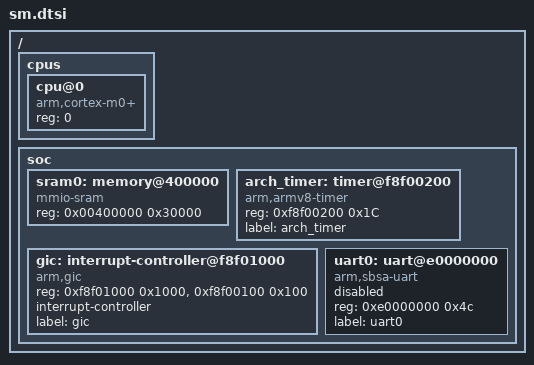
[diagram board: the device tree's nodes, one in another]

/*
 * Copyright (c) 2021 Samsung
 * SPDX-License-Identifier: Apache-2.0
 */

 #include <mem.h>
 #include <arm/armv7-a.dtsi>
 #include <dt-bindings/interrupt-controller/arm-gic.h>

/{
      cpus{
	#address-cells=<1>;
        #size-cells=<0>;
        cpu@0{	
	        device_type="cpu";
        	compatible="arm,cortex-m0+";
                reg=<0>;
        };
      };

      soc{
	

	sram0: memory@400000 {
			compatible="mmio-sram";
			reg = <0x00400000 0x30000>;
	};

        
	arch_timer: timer@f8f00200 {
		compatible = "arm,armv8-timer";
			status = "okay";
			reg = <0xf8f00200 0x1C>;
			label = "arch_timer";
	};

	gic: interrupt-controller@f8f01000 {
			compatible = "arm,gic";
			status = "okay";
			reg = <0xf8f01000 0x1000>,
				<0xf8f00100 0x100>;
			interrupt-controller;
			#interrupt-cells = <4>;
			label = "gic";
	};

	uart0: uart@e0000000 {
			compatible = "arm,sbsa-uart";
			status = "disabled";
			reg = <0xe0000000 0x4c>;
			label = "uart0";
	};              

	};
};

